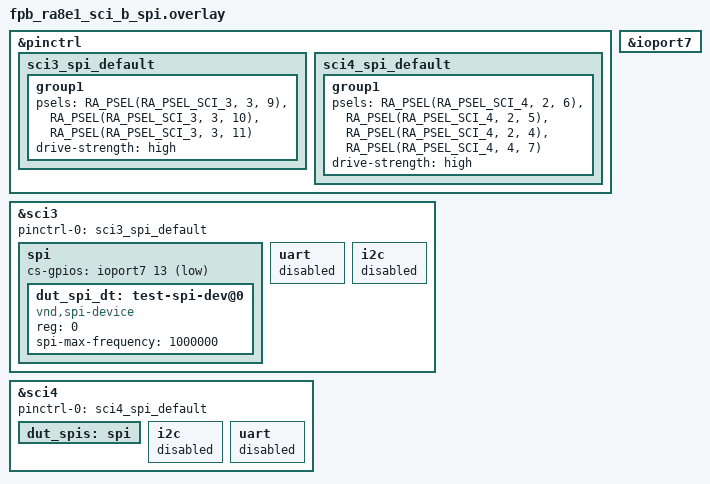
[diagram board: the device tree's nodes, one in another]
/*
 * Copyright (c) 2026 Renesas Electronics Corporation
 *
 * SPDX-License-Identifier: Apache-2.0
 */

&pinctrl {
	sci3_spi_default: sci3_spi_default {
		group1 {
			/* MISO MOSI SCK */
			psels = <RA_PSEL(RA_PSEL_SCI_3, 3, 9)>,
				<RA_PSEL(RA_PSEL_SCI_3, 3, 10)>,
				<RA_PSEL(RA_PSEL_SCI_3, 3, 11)>;
			drive-strength = "high";
		};
	};

	sci4_spi_default: sci4_spi_default {
		group1 {
			/* MISO MOSI SCK SSL */
			psels = <RA_PSEL(RA_PSEL_SCI_4, 2, 6)>,
				<RA_PSEL(RA_PSEL_SCI_4, 2, 5)>,
				<RA_PSEL(RA_PSEL_SCI_4, 2, 4)>,
				<RA_PSEL(RA_PSEL_SCI_4, 4, 7)>;
			drive-strength = "high";
		};
	};
};

&ioport7 {
	status = "okay";
};

&sci3 {
	pinctrl-0 = <&sci3_spi_default>;
	pinctrl-names = "default";

	spi {
		cs-gpios = <&ioport7 13 GPIO_ACTIVE_LOW>;
		status = "okay";

		dut_spi_dt: test-spi-dev@0 {
			compatible = "vnd,spi-device";
			reg = <0>;
			spi-max-frequency = <1000000>;
		};
	};

	uart {
		status = "disabled";
	};

	i2c {
		status = "disabled";
	};
};

&sci4 {
	pinctrl-0 = <&sci4_spi_default>;
	pinctrl-names = "default";

	dut_spis: spi {
		status = "okay";
	};

	i2c {
		status = "disabled";
	};

	uart {
		status = "disabled";
	};
};
